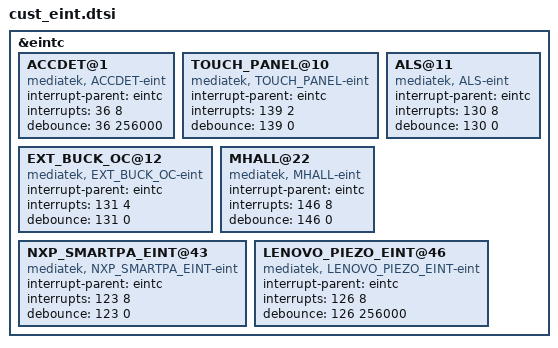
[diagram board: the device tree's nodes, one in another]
/*
 * Generated by MTK SP Drv_CodeGen Version 03.13.6  for MT6752. Copyright MediaTek Inc. (C) 2013.
 * Wed Feb  8 20:06:06 2017
 * Do Not Modify the File.
 */

/*************************
 * EINT DTSI File
*************************/

&eintc {
	ACCDET@1 {
		compatible = "mediatek, ACCDET-eint";
		interrupt-parent = <&eintc>;
		interrupts = <36 8>;
		debounce = <36 256000>;
	};

	TOUCH_PANEL@10 {
		compatible = "mediatek, TOUCH_PANEL-eint";
		interrupt-parent = <&eintc>;
		interrupts = <139 2>;
		debounce = <139 0>;
	};

	ALS@11 {
		compatible = "mediatek, ALS-eint";
		interrupt-parent = <&eintc>;
		interrupts = <130 8>;
		debounce = <130 0>;
	};

	EXT_BUCK_OC@12 {
		compatible = "mediatek, EXT_BUCK_OC-eint";
		interrupt-parent = <&eintc>;
		interrupts = <131 4>;
		debounce = <131 0>;
	};

	MHALL@22 {
		compatible = "mediatek, MHALL-eint";
		interrupt-parent = <&eintc>;
		interrupts = <146 8>;
		debounce = <146 0>;
	};

	NXP_SMARTPA_EINT@43 {
		compatible = "mediatek, NXP_SMARTPA_EINT-eint";
		interrupt-parent = <&eintc>;
		interrupts = <123 8>;
		debounce = <123 0>;
	};

	LENOVO_PIEZO_EINT@46 {
		compatible = "mediatek, LENOVO_PIEZO_EINT-eint";
		interrupt-parent = <&eintc>;
		interrupts = <126 8>;
		debounce = <126 256000>;
	};

};
